# PIC16F1032 register map
File version: 1.0
Registers are 8-bit, read-write, reset 0x0 unless marked. A register's access mark holds for its fields unless they carry their own. Offsets are from the block's base; [hi:lo] are bit positions; {n}, {i} and the like mark numbered series.

## COMPARATORS
Base 0x00800111
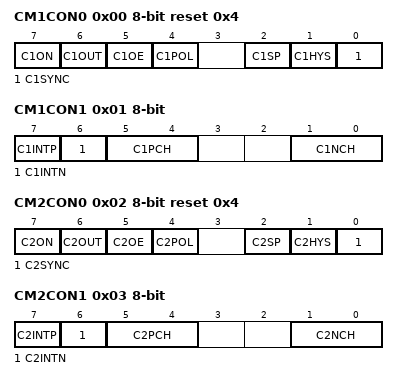
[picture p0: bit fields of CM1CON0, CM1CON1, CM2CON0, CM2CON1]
0x00 CM1CON0 reset 0x4 — CM1CON0, data address 0x111
  [7] C1ON, [6] C1OUT, [5] C1OE, [4] C1POL, [2] C1SP, [1] C1HYS, [0] C1SYNC
0x01 CM1CON1 — CM1CON1, data address 0x112
  [7] C1INTP, [6] C1INTN, [5:4] C1PCH, [1:0] C1NCH
0x02 CM2CON0 reset 0x4 — CM2CON0, data address 0x113
  [7] C2ON, [6] C2OUT, [5] C2OE, [4] C2POL, [2] C2SP, [1] C2HYS, [0] C2SYNC
0x03 CM2CON1 — CM2CON1, data address 0x114
  [7] C2INTP, [6] C2INTN, [5:4] C2PCH, [1:0] C2NCH
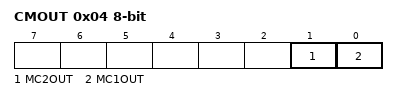
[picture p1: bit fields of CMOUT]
0x04 CMOUT — CMOUT, data address 0x115
  [1] MC2OUT, [0] MC1OUT

## EUSART
Base 0x00800199
0x00 RCREG — RCREG, data address 0x199
0x01 TXREG — TXREG, data address 0x19a
0x02 SP1BRGL — SP1BRGL, data address 0x19b
  [7:0] SPBRGL
0x03 SP1BRGH — SP1BRGH, data address 0x19c
  [7:0] SPBRGH
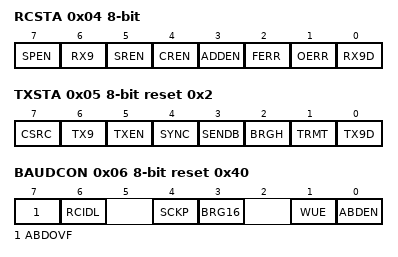
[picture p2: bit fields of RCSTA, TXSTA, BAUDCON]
0x04 RCSTA (reset mask 0xFE) — RCSTA, data address 0x19d
  [7] SPEN, [6] RX9, [5] SREN, [4] CREN, [3] ADDEN, [2] FERR, [1] OERR, [0] RX9D
0x05 TXSTA reset 0x2 — TXSTA, data address 0x19e
  [7] CSRC, [6] TX9, [5] TXEN, [4] SYNC, [3] SENDB, [2] BRGH, [1] TRMT, [0] TX9D
0x06 BAUDCON reset 0x40 — BAUDCON, data address 0x19f
  [7] ABDOVF, [6] RCIDL, [4] SCKP, [3] BRG16, [1] WUE, [0] ABDEN

## INTERRUPTS — Interrupt flags and enables
Base 0x00800011
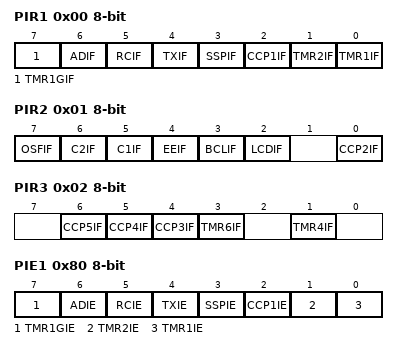
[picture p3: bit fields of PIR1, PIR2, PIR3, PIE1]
0x00 PIR1 — PIR1, data address 0x011
  [7] TMR1GIF, [6] ADIF, [5] RCIF, [4] TXIF, [3] SSPIF, [2] CCP1IF, [1] TMR2IF, [0] TMR1IF
0x01 PIR2 — PIR2, data address 0x012
  [7] OSFIF, [6] C2IF, [5] C1IF, [4] EEIF, [3] BCLIF, [2] LCDIF, [0] CCP2IF
0x02 PIR3 — PIR3, data address 0x013
  [6] CCP5IF, [5] CCP4IF, [4] CCP3IF, [3] TMR6IF, [1] TMR4IF
0x80 PIE1 — PIE1, data address 0x091
  [7] TMR1GIE, [6] ADIE, [5] RCIE, [4] TXIE, [3] SSPIE, [2] CCP1IE, [1] TMR2IE, [0] TMR1IE
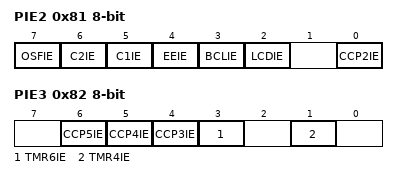
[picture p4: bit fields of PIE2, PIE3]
0x81 PIE2 — PIE2, data address 0x092
  [7] OSFIE, [6] C2IE, [5] C1IE, [4] EEIE, [3] BCLIE, [2] LCDIE, [0] CCP2IE
0x82 PIE3 — PIE3, data address 0x093
  [6] CCP5IE, [5] CCP4IE, [4] CCP3IE, [3] TMR6IE, [1] TMR4IE

## LCD — LCD driver
Base 0x00800791
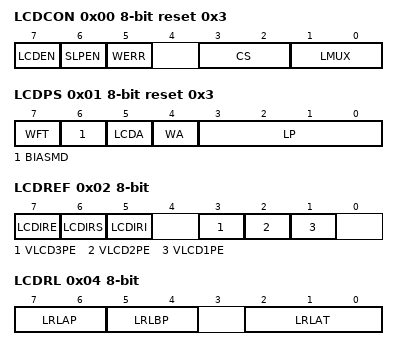
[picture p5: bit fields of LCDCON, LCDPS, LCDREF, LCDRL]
0x00 LCDCON reset 0x3 — LCDCON, data address 0x791
  [7] LCDEN, [6] SLPEN, [5] WERR, [3:2] CS, [1:0] LMUX
0x01 LCDPS reset 0x3 — LCDPS, data address 0x792
  [7] WFT, [6] BIASMD, [5] LCDA, [4] WA, [3:0] LP
0x02 LCDREF — LCDREF, data address 0x793
  [7] LCDIRE, [6] LCDIRS, [5] LCDIRI, [3] VLCD3PE, [2] VLCD2PE, [1] VLCD1PE
0x03 LCDCST — LCDCST, data address 0x794
  [2:0] LCDCST
0x04 LCDRL — LCDRL, data address 0x795
  [7:6] LRLAP, [5:4] LRLBP, [2:0] LRLAT
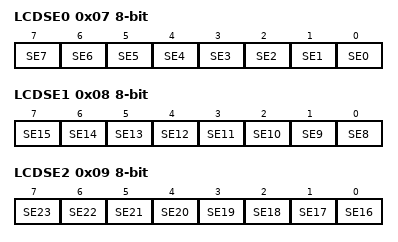
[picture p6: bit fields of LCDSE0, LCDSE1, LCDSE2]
0x07 LCDSE0 — LCDSE0, data address 0x798
  [n] SE{n} (n=0..7)
0x08 LCDSE1 — LCDSE1, data address 0x799
  [n-8] SE{n} (n=8..15)
0x09 LCDSE2 — LCDSE2, data address 0x79a
  [n-16] SE{n} (n=16..23)

## MSSP — Synchronous serial port
Base 0x00800211
0x00 SSPBUF reset not defined — SSPBUF, data address 0x211
0x01 SSPADD — SSPADD, data address 0x212
0x02 SSPMSK reset 0xFF — SSPMSK, data address 0x213
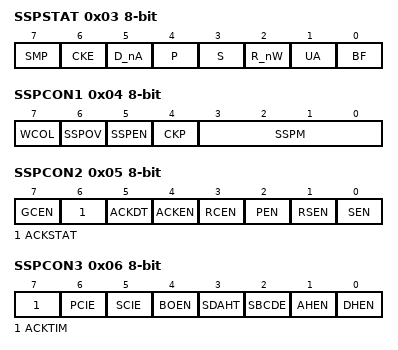
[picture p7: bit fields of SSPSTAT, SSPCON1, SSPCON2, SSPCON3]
0x03 SSPSTAT — SSPSTAT, data address 0x214
  [7] SMP, [6] CKE, [5] D_nA, [4] P, [3] S, [2] R_nW, [1] UA, [0] BF
0x04 SSPCON1 — SSPCON1, data address 0x215
  [7] WCOL, [6] SSPOV, [5] SSPEN, [4] CKP, [3:0] SSPM
0x05 SSPCON2 — SSPCON2, data address 0x216
  [7] GCEN, [6] ACKSTAT, [5] ACKDT, [4] ACKEN, [3] RCEN, [2] PEN, [1] RSEN, [0] SEN
0x06 SSPCON3 (reset mask 0x9F) — SSPCON3, data address 0x217
  [7] ACKTIM, [6] PCIE, [5] SCIE, [4] BOEN, [3] SDAHT, [2] SBCDE, [1] AHEN, [0] DHEN

## NVM — Flash and EEPROM access
Base 0x00800191
0x00 EEADRL — EEADRL, data address 0x191
0x01 EEADRH reset 0x80 — EEADRH, data address 0x192
  [6:0] EEADRH
0x02 EEDATL reset not defined — EEDATL, data address 0x193
0x03 EEDATH reset not defined — EEDATH, data address 0x194
  [5:0] EEDATH
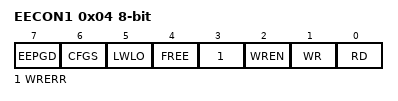
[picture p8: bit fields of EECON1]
0x04 EECON1 (reset mask 0xF7) — EECON1, data address 0x195
  [7] EEPGD, [6] CFGS, [5] LWLO, [4] FREE, [3] WRERR, [2] WREN, [1] WR, [0] RD
0x05 EECON2 reset not defined — EECON2, data address 0x196
